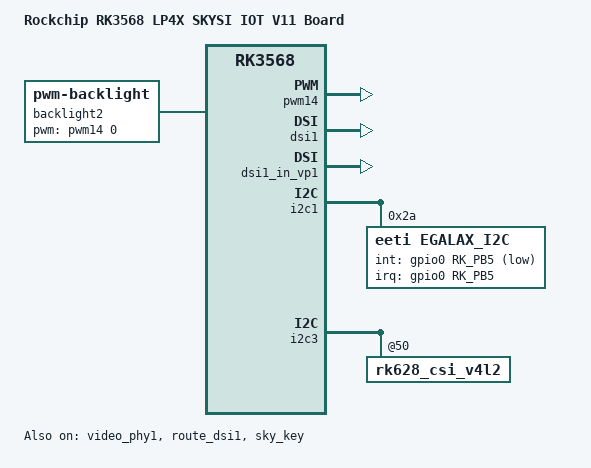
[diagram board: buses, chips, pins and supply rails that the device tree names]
// SPDX-License-Identifier: (GPL-2.0+ OR MIT)
/*
 * Copyright (c) 2020 Rockchip Electronics Co., Ltd.
 *
 */

#include "rk3568-evb-lp4x-s1-v11.dtsi"
#include "rk3568-android.dtsi"
/{
	model = "Rockchip RK3568 LP4X SKYSI IOT V11 Board";
	compatible = "rockchip,rk3568-iot-lp4x-s1-v11-mipi", "rockchip,rk3568";

	backlight2: backlight2 {
		compatible = "pwm-backlight";
		pwms = <&pwm14 0 25000 0>;
		brightness-levels = <
			  0   1   2   3   4   5   6   7
			  8   9  10  11  12  13  14  15
			 16  17  18  19  20  21  22  23
			 24  25  26  27  28  29  30  31
			 32  33  34  35  36  37  38  39
			 40  41  42  43  44  45  46  47
			 48  49  50  51  52  53  54  55
			 56  57  58  59  60  61  62  63
			 64  65  66  67  68  69  70  71
			 72  73  74  75  76  77  78  79
			 80  81  82  83  84  85  86  87
			 88  89  90  91  92  93  94  95
			 96  97  98  99 100 101 102 103
			104 105 106 107 108 109 110 111
			112 113 114 115 116 117 118 119
			120 121 122 123 124 125 126 127
			128 129 130 131 132 133 134 135
			136 137 138 139 140 141 142 143
			144 145 146 147 148 149 150 151
			152 153 154 155 156 157 158 159
			160 161 162 163 164 165 166 167
			168 169 170 171 172 173 174 175
			176 177 178 179 180 181 182 183
			184 185 186 187 188 189 190 191
			192 193 194 195 196 197 198 199
			200 201 202 203 204 205 206 207
			208 209 210 211 212 213 214 215
			216 217 218 219 220 221 222 223
			224 225 226 227 228 229 230 231
			232 233 234 235 236 237 238 239
			240 241 242 243 244 245 246 247
			248 249 250 251 252 253 254 255
		>;
		default-brightness-level = <200>;
	};
};

&pwm14 {
	status = "okay";
	pinctrl-0 = <&pwm14m1_pins>;
};

&video_phy0 {
	status = "disabled";
};

&video_phy1 {
	status = "okay";
};

/*
 * video_phy1 needs to be enabled
 * when dsi1 is enabled
 */
&dsi1 {
	status = "okay";
};

&dsi1_in_vp0 {
	status = "disabled";
};

&dsi1_in_vp1 {
	status = "okay";
};

&dsi1_panel {
	backlight = <&backlight2>;
	power-supply = <&vcc3v3_lcd1_n>;
	enable-gpios = <&gpio2 RK_PD4 GPIO_ACTIVE_HIGH>;
	reset-gpios = <&gpio3 RK_PC7 GPIO_ACTIVE_LOW>;
	enable-delay-ms = <10>;
	prepare-delay-ms = <20>;
	reset-delay-ms = <10>;
	reset1-delay-ms = <10>;
	init-delay-ms = <10>;
	unprepare-delay-ms = <50>;
	disable-delay-ms = <20>;

	panel-init-sequence = [
		39 01 03 E0 AB BA
		39 01 03 E1 BA AB
		39 01 05 B1 10 01 47 FF
		39 01 07 B2 0C 10 04 50 50 14

		39 01 04 B3 56 D3 00
		39 01 04 B4 33 30 04
		39 01 08 B6 B0 00 00 10 00 10 00
		39 01 06 B8 36 12 29 49 48

		39 01 27 B9 7F 67 55 49 44 34 38 23 3E 3F 3F 5D 4B 52 44 41 36 24 06 7F 67 55 49 44 34 38 23 3E 3F 3F 5D 4B 52 44 41 36 24 06

		39 01 11 C0 32 45 B4 45 66 44 44 44 90 04 86 04 3F 00 00 C1
		39 01 0B C1 34 94 02 8F 90 04 86 04 54 00
		39 01 0D C2 33 09 08 89 08 11 22 20 44 BB 18 00
		39 01 17 C3 80 40 08 07 06 13 12 11 10 0F 0E 0D 0C 04 05 02 02 02 02 02 02 00
		39 01 17 C4 00 00 08 07 06 13 12 11 10 0F 0E 0D 0C 04 05 02 02 02 02 02 02 02

		39 01 03 C6 25 25
		39 01 07 C8 21 00 31 42 34 16
		39 01 03 CA CB 43
		39 01 09 CD 0E 6E 6E 20 19 6B 06 b3
		39 01 05 D2 E3 2B 38 00
		39 01 0C D4 00 01 00 0E 04 44 08 10 00 00 00
		39 01 09 E6 80 01 FF FF FF FF FF FF
		39 01 06 F0 12 03 20 00 FF
		15 01 02 F3 00
		05 01 01 11
		05 01 01 29
	];

	panel-exit-sequence = [
		05 01 01 28
		05 01 01 10
	];

	disp_timings1: display-timings {
		native-mode = <&dsi1_timing0>;

		dsi1_timing0: timing0 {
			clock-frequency = <76800000>;
			hactive = <800>;
			vactive = <1280>;
			hfront-porch = <80>;
			hsync-len = <20>;
			hback-porch = <80>;
			vfront-porch = <20>;
			vsync-len = <4>;
			vback-porch = <12>;
			hsync-active = <0>;
			vsync-active = <0>;
			de-active = <0>;
			pixelclk-active = <0>;
		};
	};
};

&route_dsi1 {
	status = "okay";
	logo,uboot = "logo.bmp";
	logo,kernel = "logo.bmp";
	connect = <&vp1_out_dsi1>;
};

&i2c1 {
	status = "okay";

	egalax_i2c@2a {
		compatible = "eeti,egalax_i2c";
		reg = <0x2a>;
		interrupt-parent = <&gpio0>;
		interrupts = <RK_PB5 IRQ_TYPE_LEVEL_LOW>;
		int-gpios = <&gpio0 RK_PB5 GPIO_ACTIVE_LOW>;
	};
};

&i2c3 {
	rk628_csi_v4l2: rk628_csi_v4l2@50 {
		status = "okay";
	    pinctrl-0 = <&rk628_irq &rk628_det &refclk_pins>;
	};
};

&sky_key{
	dpi = "100";
	vertical-dpi = "160";
	status = "okay";
};
